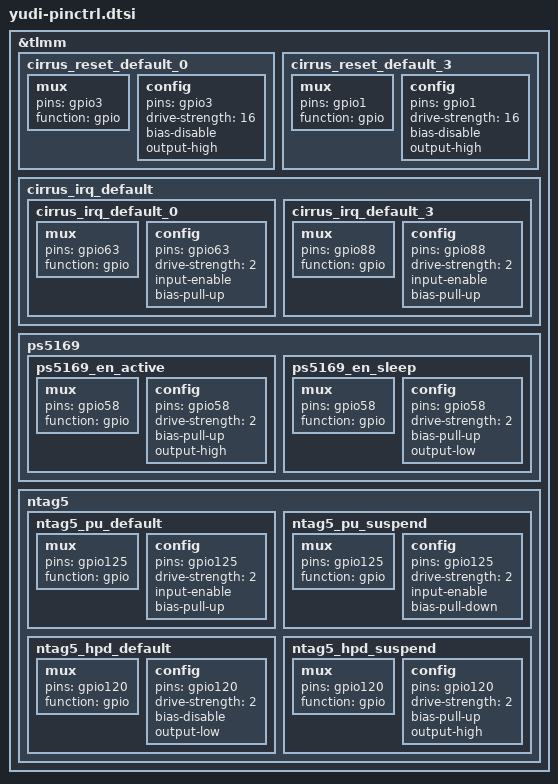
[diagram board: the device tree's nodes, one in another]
/*for unicorn pinctrl */
&tlmm {
	cirrus_reset_default_0: cirrus_reset_default_0 {
		mux {
			pins = "gpio3";
			function = "gpio";
		};
		config {
			pins = "gpio3";
			drive-strength = <16>;   /* 16 mA */
			bias-disable;
			output-high;
		};
	};
	cirrus_reset_default_3: cirrus_reset_default_3 {
		mux {
			pins = "gpio1";
			function = "gpio";
		};
		config {
			pins = "gpio1";
			drive-strength = <16>;   /* 16 mA */
			bias-disable;
			output-high;
		};
	};
	cirrus_irq_default {
		cirrus_irq_default_0: cirrus_irq_default_0 {
			mux {
				pins = "gpio63";
				function = "gpio";
			};
			config {
				pins = "gpio63";
				drive-strength = <2>;
				input-enable;
				bias-pull-up;
			};
		};
		cirrus_irq_default_3: cirrus_irq_default_3 {
			mux {
				pins = "gpio88";
				function = "gpio";
			};
			config {
				pins = "gpio88";
				drive-strength = <2>;
				input-enable;
				bias-pull-up;
			};
		};
	};
	ps5169 {
		ps5169_en_active: ps5169_en_active {
			mux {
				pins = "gpio58";
				function = "gpio";
			};

			config {
				pins = "gpio58";
				drive-strength = <2>;
				bias-pull-up;
				output-high;
			};
		};

		ps5169_en_sleep: ps5169_en_sleep {
			mux {
				pins = "gpio58";
				function = "gpio";
			};

			config {
				pins = "gpio58";
				drive-strength = <2>;
				bias-pull-up;
				output-low;
			};
		};
	};
	ntag5 {
			ntag5_pu_default: ntag5_pu_default {
					mux {
						pins = "gpio125";
						function = "gpio";
					};

					config {
						pins = "gpio125";
						drive-strength = <2>; /* 2 MA */
						input-enable;
						/* 拉高方式恢复 */
						bias-pull-up;
					};
			};

			ntag5_pu_suspend: ntag5_pu_suspend {
					mux {
						pins = "gpio125";
						function = "gpio";
					};

					config {
						pins = "gpio125";
						drive-strength = <2>; /* 2 MA */
						input-enable;
						/* 拉低方式触发 */
						bias-pull-down;
					};
			};

			ntag5_hpd_default: ntag5_hpd_default {
					mux {
						pins = "gpio120";
						function = "gpio";
					};

					config {
						pins = "gpio120";
						drive-strength = <2>; /* 2 MA */
						// 默认态 bias-disable是悬空
						bias-disable;
						output-low;
					};
			};

			ntag5_hpd_suspend: ntag5_hpd_suspend {
					mux {
						pins = "gpio120";
						function = "gpio";
					};

					config {
						pins = "gpio120";
						drive-strength = <2>; /* 2 MA */
						/* 拉高方式触发 */
						bias-pull-up;
						output-high;
					};
			};
		};
};

